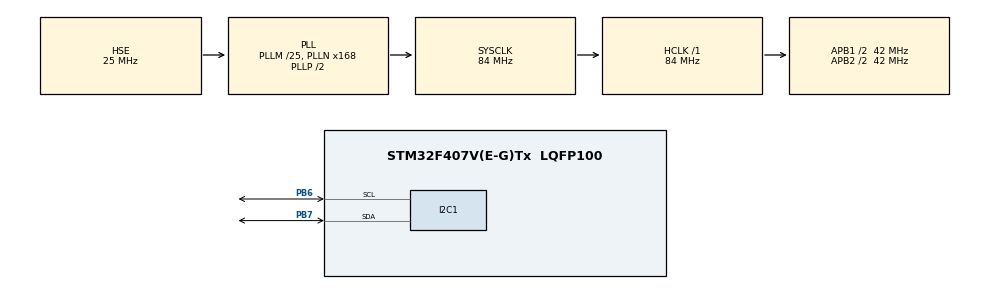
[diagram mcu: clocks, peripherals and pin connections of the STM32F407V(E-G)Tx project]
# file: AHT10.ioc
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Mcu.Family=STM32F4
Mcu.Name=STM32F407V(E-G)Tx
Mcu.Package=LQFP100
NVIC.I2C1_EV_IRQn=true\:0\:0\:false\:false\:true\:true\:true
NVIC.PriorityGroup=NVIC_PRIORITYGROUP_4
NVIC.TIM2_IRQn=true\:0\:0\:false\:false\:true\:true\:true
PB6.Mode=I2C
PB6.Signal=I2C1_SCL
PB7.Mode=I2C
PB7.Signal=I2C1_SDA
PH0-OSC_IN.Mode=HSE-External-Oscillator
PH0-OSC_IN.Signal=RCC_OSC_IN
PH1-OSC_OUT.Mode=HSE-External-Oscillator
PH1-OSC_OUT.Signal=RCC_OSC_OUT
ProjectManager.HeapSize=0x200
ProjectManager.StackSize=0x400
ProjectManager.TargetToolchain=STM32CubeIDE
RCC.48MHZClocksFreq_Value=42000000
RCC.AHBFreq_Value=84000000
RCC.APB1CLKDivider=RCC_HCLK_DIV2
RCC.APB1Freq_Value=42000000
RCC.APB1TimFreq_Value=84000000
RCC.APB2CLKDivider=RCC_HCLK_DIV2
RCC.APB2Freq_Value=42000000
RCC.APB2TimFreq_Value=84000000
RCC.CortexFreq_Value=84000000
RCC.HCLKFreq_Value=84000000
RCC.HSE_VALUE=25000000
RCC.HSI_VALUE=16000000
RCC.LSE_VALUE=32768
RCC.PLLM=25
RCC.PLLN=168
RCC.PLLSourceVirtual=RCC_PLLSOURCE_HSE
RCC.SYSCLKFreq_VALUE=84000000
RCC.SYSCLKSource=RCC_SYSCLKSOURCE_PLLCLK
RCC.VCOOutputFreq_Value=168000000
TIM2.Period=999
TIM2.Prescaler=8399
VP_TIM2_VS_ClockSourceINT.Mode=Internal
board=custom

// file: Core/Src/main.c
/* USER CODE BEGIN Header */
/**
  ******************************************************************************
  * @file           : main.c
  * @brief          : Main program body
  ******************************************************************************
  * @attention
  *
  * <h2><center>&copy; Copyright (c) 2021 STMicroelectronics.
  * All rights reserved.</center></h2>
  *
  * This software component is licensed by ST under BSD 3-Clause license,
  * the "License"; You may not use this file except in compliance with the
  * License. You may obtain a copy of the License at:
  *                        opensource.org/licenses/BSD-3-Clause
  *
  ******************************************************************************
  */
/* USER CODE END Header */
#include "main.h"

I2C_HandleTypeDef hi2c1;

TIM_HandleTypeDef htim2;

/* USER CODE BEGIN PV */
uint8_t T_100=255;
float Temperature, Humidity;
uint8_t  Switch=255, RX_data[6];
uint32_t ADC_RawData;
uint8_t TMP_Hum_Cmd[3]={0xAC, 0x33, 0x00};
/* USER CODE END PV */

void SystemClock_Config(void);
static void MX_GPIO_Init(void);
static void MX_I2C1_Init(void);
static void MX_TIM2_Init(void);
/* USER CODE BEGIN PFP */
void temp_read(void);
/* USER CODE END PFP */

/* USER CODE BEGIN 0 */

/*@brief HAL_TIM_PeriodElapsedCallback, Timer function works when timer accurs.
 * 										Timer can adjust maximum 20 ms because AHT10 reach idle state at most 20 ms high in SCL.
 *@params htim = TIM Output Compare handle
 *
 * @retval None
 */
void HAL_TIM_PeriodElapsedCallback(TIM_HandleTypeDef *htim)
{
 if(htim->Instance == TIM2)
 {
	/* Set every 100ms */
	T_100 = 255;
 }
}
/* USER CODE END 0 */

int main(void)
{

  /* MCU Configuration--------------------------------------------------------*/

  /* Reset of all peripherals, Initializes the Flash interface and the Systick. */
  HAL_Init();

  /* Configure the system clock */
  SystemClock_Config();

  /* Initialize all configured peripherals */
  MX_GPIO_Init();
  MX_I2C1_Init();
  MX_TIM2_Init();
  /* USER CODE BEGIN 2 */
  HAL_TIM_Base_Start_IT(&htim2);
  /* USER CODE END 2 */

  /* Infinite loop */
  while (1)
  {

    /* USER CODE BEGIN 3 */
	  temp_read();				//Call temperature read function.

  }
  /* USER CODE END 3 */
}

void SystemClock_Config(void)
{
  RCC_OscInitTypeDef RCC_OscInitStruct = {0};
  RCC_ClkInitTypeDef RCC_ClkInitStruct = {0};

  /** Configure the main internal regulator output voltage
  */
  __HAL_RCC_PWR_CLK_ENABLE();
  __HAL_PWR_VOLTAGESCALING_CONFIG(PWR_REGULATOR_VOLTAGE_SCALE1);
  /** Initializes the RCC Oscillators according to the specified parameters
  * in the RCC_OscInitTypeDef structure.
  */
  RCC_OscInitStruct.OscillatorType = RCC_OSCILLATORTYPE_HSE;
  RCC_OscInitStruct.HSEState = RCC_HSE_ON;
  RCC_OscInitStruct.PLL.PLLState = RCC_PLL_ON;
  RCC_OscInitStruct.PLL.PLLSource = RCC_PLLSOURCE_HSE;
  RCC_OscInitStruct.PLL.PLLM = 25;
  RCC_OscInitStruct.PLL.PLLN = 168;
  RCC_OscInitStruct.PLL.PLLP = RCC_PLLP_DIV2;
  RCC_OscInitStruct.PLL.PLLQ = 4;
  if (HAL_RCC_OscConfig(&RCC_OscInitStruct) != HAL_OK)
  {
    Error_Handler();
  }
  /** Initializes the CPU, AHB and APB buses clocks
  */
  RCC_ClkInitStruct.ClockType = RCC_CLOCKTYPE_HCLK|RCC_CLOCKTYPE_SYSCLK
                              |RCC_CLOCKTYPE_PCLK1|RCC_CLOCKTYPE_PCLK2;
  RCC_ClkInitStruct.SYSCLKSource = RCC_SYSCLKSOURCE_PLLCLK;
  RCC_ClkInitStruct.AHBCLKDivider = RCC_SYSCLK_DIV1;
  RCC_ClkInitStruct.APB1CLKDivider = RCC_HCLK_DIV2;
  RCC_ClkInitStruct.APB2CLKDivider = RCC_HCLK_DIV2;

  if (HAL_RCC_ClockConfig(&RCC_ClkInitStruct, FLASH_LATENCY_2) != HAL_OK)
  {
    Error_Handler();
  }
}

static void MX_I2C1_Init(void)
{

  hi2c1.Instance = I2C1;
  hi2c1.Init.ClockSpeed = 100000;
  hi2c1.Init.DutyCycle = I2C_DUTYCYCLE_2;
  hi2c1.Init.OwnAddress1 = 0;
  hi2c1.Init.AddressingMode = I2C_ADDRESSINGMODE_7BIT;
  hi2c1.Init.DualAddressMode = I2C_DUALADDRESS_DISABLE;
  hi2c1.Init.OwnAddress2 = 0;
  hi2c1.Init.GeneralCallMode = I2C_GENERALCALL_DISABLE;
  hi2c1.Init.NoStretchMode = I2C_NOSTRETCH_DISABLE;
  if (HAL_I2C_Init(&hi2c1) != HAL_OK)
  {
    Error_Handler();
  }

}

static void MX_TIM2_Init(void)
{

  TIM_ClockConfigTypeDef sClockSourceConfig = {0};
  TIM_MasterConfigTypeDef sMasterConfig = {0};

  htim2.Instance = TIM2;
  htim2.Init.Prescaler = 8399;
  htim2.Init.CounterMode = TIM_COUNTERMODE_UP;
  htim2.Init.Period = 999;
  htim2.Init.ClockDivision = TIM_CLOCKDIVISION_DIV1;
  htim2.Init.AutoReloadPreload = TIM_AUTORELOAD_PRELOAD_DISABLE;
  if (HAL_TIM_Base_Init(&htim2) != HAL_OK)
  {
    Error_Handler();
  }
  sClockSourceConfig.ClockSource = TIM_CLOCKSOURCE_INTERNAL;
  if (HAL_TIM_ConfigClockSource(&htim2, &sClockSourceConfig) != HAL_OK)
  {
    Error_Handler();
  }
  sMasterConfig.MasterOutputTrigger = TIM_TRGO_RESET;
  sMasterConfig.MasterSlaveMode = TIM_MASTERSLAVEMODE_DISABLE;
  if (HAL_TIMEx_MasterConfigSynchronization(&htim2, &sMasterConfig) != HAL_OK)
  {
    Error_Handler();
  }

}

static void MX_GPIO_Init(void)
{

  /* GPIO Ports Clock Enable */
  __HAL_RCC_GPIOH_CLK_ENABLE();
  __HAL_RCC_GPIOB_CLK_ENABLE();

}

/* USER CODE BEGIN 4 */

/**
  * @brief temp_read, Temperature and Humidity read function
  * @param None
  * @retval None
  */
void temp_read(void){

	if(T_100){				//Waits until timer counts.
			  if(Switch){
				  HAL_I2C_Master_Transmit_IT(&hi2c1, Addr, (uint8_t*)TMP_Hum_Cmd, 3);								// Send CMD command for AHT10
			  }
			  else{
				  HAL_I2C_Master_Receive_IT(&hi2c1, Addr, RX_data, 6);												// Read from AHT10
			  }
			  if(~RX_data[0] & 0x80){
				  ADC_RawData=(((uint32_t)RX_data[3] & 15) << 16) | ((uint32_t)RX_data[4] << 8) | RX_data[5];
				  Temperature=(float)(ADC_RawData * 200 / 1048576.00)-50;											//Temperature conversion

				  ADC_RawData=((uint32_t)RX_data[1] & 12) | ((uint32_t)RX_data[2] << 4) | RX_data[3]>>4;
				  Humidity=(float)(ADC_RawData*100.00/1048576.00);													//Humidity conversion
				  Humidity *=  100;
			  }
			  Switch = ~Switch;
			  T_100 = 0;																							//Reset timer counter

		  }
}
/* USER CODE END 4 */

void Error_Handler(void)
{
  __disable_irq();
  while (1)
  {
  }
}

/************************ (C) COPYRIGHT STMicroelectronics *****END OF FILE****/
